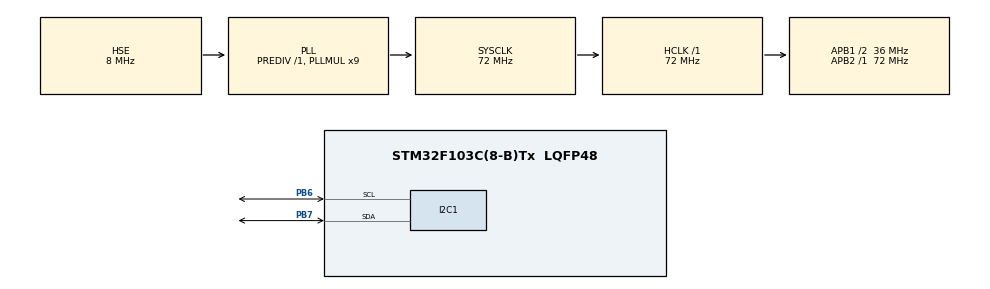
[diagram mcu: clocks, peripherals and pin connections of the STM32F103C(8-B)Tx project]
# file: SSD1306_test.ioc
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I2C1.I2C_Mode=I2C_Fast
Mcu.Family=STM32F1
Mcu.Name=STM32F103C(8-B)Tx
Mcu.Package=LQFP48
NVIC.PriorityGroup=NVIC_PRIORITYGROUP_4
NVIC.TIM4_IRQn=true\:0\:0\:false\:false\:true\:false
NVIC.TimeBase=TIM4_IRQn
NVIC.TimeBaseIP=TIM4
PA13.Mode=Serial_Wire
PA13.Signal=SYS_JTMS-SWDIO
PA14.Mode=Serial_Wire
PA14.Signal=SYS_JTCK-SWCLK
PB3.Signal=SYS_JTDO-TRACESWO
PB6.Mode=I2C
PB6.Signal=I2C1_SCL
PB7.Mode=I2C
PB7.Signal=I2C1_SDA
PD0-OSC_IN.Mode=HSE-External-Oscillator
PD0-OSC_IN.Signal=RCC_OSC_IN
PD1-OSC_OUT.Mode=HSE-External-Oscillator
PD1-OSC_OUT.Signal=RCC_OSC_OUT
ProjectManager.HeapSize=0x200
ProjectManager.StackSize=0x400
ProjectManager.TargetToolchain=SW4STM32
RCC.AHBFreq_Value=72000000
RCC.APB1CLKDivider=RCC_HCLK_DIV2
RCC.APB1Freq_Value=36000000
RCC.APB1TimFreq_Value=72000000
RCC.APB2Freq_Value=72000000
RCC.APB2TimFreq_Value=72000000
RCC.HCLKFreq_Value=72000000
RCC.PLLMUL=RCC_PLL_MUL9
RCC.PLLSourceVirtual=RCC_PLLSOURCE_HSE
RCC.SYSCLKFreq_VALUE=72000000
RCC.SYSCLKSource=RCC_SYSCLKSOURCE_PLLCLK
RCC.USBFreq_Value=72000000
VP_SYS_VS_tim4.Mode=TIM4
board=custom

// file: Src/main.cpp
/* USER CODE BEGIN Header */
/**
  ******************************************************************************
  * @file           : main.c
  * @brief          : Main program body
  ******************************************************************************
  ** This notice applies to any and all portions of this file
  * that are not between comment pairs USER CODE BEGIN and
  * USER CODE END. Other portions of this file, whether
  * inserted by the user or by software development tools
  * are owned by their respective copyright owners.
  *
  * COPYRIGHT(c) 2019 STMicroelectronics
  *
  * Redistribution and use in source and binary forms, with or without modification,
  * are permitted provided that the following conditions are met:
  *   1. Redistributions of source code must retain the above copyright notice,
  *      this list of conditions and the following disclaimer.
  *   2. Redistributions in binary form must reproduce the above copyright notice,
  *      this list of conditions and the following disclaimer in the documentation
  *      and/or other materials provided with the distribution.
  *   3. Neither the name of STMicroelectronics nor the names of its contributors
  *      may be used to endorse or promote products derived from this software
  *      without specific prior written permission.
  *
  * THIS SOFTWARE IS PROVIDED BY THE COPYRIGHT HOLDERS AND CONTRIBUTORS "AS IS"
  * AND ANY EXPRESS OR IMPLIED WARRANTIES, INCLUDING, BUT NOT LIMITED TO, THE
  * IMPLIED WARRANTIES OF MERCHANTABILITY AND FITNESS FOR A PARTICULAR PURPOSE ARE
  * DISCLAIMED. IN NO EVENT SHALL THE COPYRIGHT HOLDER OR CONTRIBUTORS BE LIABLE
  * FOR ANY DIRECT, INDIRECT, INCIDENTAL, SPECIAL, EXEMPLARY, OR CONSEQUENTIAL
  * DAMAGES (INCLUDING, BUT NOT LIMITED TO, PROCUREMENT OF SUBSTITUTE GOODS OR
  * SERVICES; LOSS OF USE, DATA, OR PROFITS; OR BUSINESS INTERRUPTION) HOWEVER
  * CAUSED AND ON ANY THEORY OF LIABILITY, WHETHER IN CONTRACT, STRICT LIABILITY,
  * OR TORT (INCLUDING NEGLIGENCE OR OTHERWISE) ARISING IN ANY WAY OUT OF THE USE
  * OF THIS SOFTWARE, EVEN IF ADVISED OF THE POSSIBILITY OF SUCH DAMAGE.
  *
  ******************************************************************************
  */
/* USER CODE END Header */

#include "main.h"
#include <string.h>

/* USER CODE BEGIN PD */
#define SCALESPEED 0.025
/* USER CODE END PD */

I2C_HandleTypeDef hi2c1;

void SystemClock_Config(void);
static void MX_GPIO_Init(void);
static void MX_I2C1_Init(void);

/* USER CODE BEGIN 0 */
Scene3D scene(64, 32, 6, 6); // 128x64

// model defines

/* USER CODE END 0 */

int main(void)
{
  /* USER CODE BEGIN 1 */
	// INIT MODEL

	Matrix<> vertex(4, 8, ver);
	Matrix<int> faces(9, 3, fa);
	Matrix<int> im(3, 2, ima); // 1, 24

	scene.addModel(vertex, faces, im);
//	scene.addModel(vertex, faces, im);
//	scene.addModel(vertex, faces, im);
//	scene.addModel(vertex, faces, im);

//	scene.addModel(vertex, faces, im);
  /* USER CODE END 1 */

  /* MCU Configuration--------------------------------------------------------*/

  /* Reset of all peripherals, Initializes the Flash interface and the Systick. */
  HAL_Init();

  /* Configure the system clock */
  SystemClock_Config();

  /* Initialize all configured peripherals */
  MX_GPIO_Init();
  MX_I2C1_Init();

  /* USER CODE BEGIN 2 */
  uint32_t end = 0;
  uint32_t start;
  uint32_t scalingCount = 1;
  bool scalingD = true;
  int fps3d = 0, fpsre = 0;
  ssd1306_Init();
  scene.apply(translation3D(0,-2,0));
  /* USER CODE END 2 */

  /* Infinite loop */
  while (1)
  {
	  start = HAL_GetTick();

	  scene.Clear();
	  scene.render();

	  // transforms
	  scene.apply(rotationY(3.14/24));
	  scene.apply(rotationX(3.14/36));

//	  if (scalingD && scalingCount < 10)
//	  {
//		  scene.apply(scaling3D(1 - SCALESPEED, 1 - SCALESPEED, 1 - SCALESPEED));
//		  scalingCount++;
//	  }
//	  else
//		  if (scalingCount > 0)
//		  {
//			  scalingD = false;
//			  scene.apply(scaling3D(1 + SCALESPEED, 1 + SCALESPEED, 1 + SCALESPEED));
//			  scalingCount--;
//		  }
//		  else
//		  {
//			  scene.apply(scaling3D(1 - SCALESPEED, 1 - SCALESPEED, 1 - SCALESPEED));
//			  scalingD = true;
//			  scalingCount = 1;
//		  }

	  end = HAL_GetTick();

	  // 3D engine FPS count
	  // char buff[8];
	  // fps3d = 1000 / (end - start);

	  // display all FPS
	  // snprintf(buff, sizeof(buff), "%d", fps3d);
	  // ssd1306_SetCursor(0,0);
	  // ssd1306_WriteString(buff, Font_7x10, White);
	  snprintf(buff, sizeof(buff), "%d", fpsre);
	  ssd1306_SetCursor(0,0);
	  ssd1306_WriteString(buff, Font_7x10, White);

	  ssd1306_UpdateScreen();

	  // Real FPS count
	  end = HAL_GetTick();
	  fpsre = 1000 / (end - start);

	  ssd1306_UpdateScreen();

//	  ssd1306_SetCursor(0,0);
//	  ssd1306_WriteString("HELLO!", Font_7x10, White); //пишем надпись в выставленной позиции шрифтом "Font_7x10" белым цветом.
//
//	  for (int i = 0; i < 63; i+=4)
//		  ssd1306_DrawLine(47, 31,  127, i,  White);
//	  ssd1306_DrawFilledRectangle(15, 15, 31, 31, White);
//	  ssd1306_DrawFilledCircle(63, 31, 10, White);
//
//
//	  ssd1306_UpdateScreen();
//
//	  ssd1306_Fill(Black);

  }
}

void SystemClock_Config(void)
{
  RCC_OscInitTypeDef RCC_OscInitStruct = {0};
  RCC_ClkInitTypeDef RCC_ClkInitStruct = {0};

  /**Initializes the CPU, AHB and APB busses clocks
  */
  RCC_OscInitStruct.OscillatorType = RCC_OSCILLATORTYPE_HSE;
  RCC_OscInitStruct.HSEState = RCC_HSE_ON;
  RCC_OscInitStruct.HSEPredivValue = RCC_HSE_PREDIV_DIV1;
  RCC_OscInitStruct.HSIState = RCC_HSI_ON;
  RCC_OscInitStruct.PLL.PLLState = RCC_PLL_ON;
  RCC_OscInitStruct.PLL.PLLSource = RCC_PLLSOURCE_HSE;
  RCC_OscInitStruct.PLL.PLLMUL = RCC_PLL_MUL9;
  if (HAL_RCC_OscConfig(&RCC_OscInitStruct) != HAL_OK)
  {
    Error_Handler();
  }
  /**Initializes the CPU, AHB and APB busses clocks
  */
  RCC_ClkInitStruct.ClockType = RCC_CLOCKTYPE_HCLK|RCC_CLOCKTYPE_SYSCLK
                              |RCC_CLOCKTYPE_PCLK1|RCC_CLOCKTYPE_PCLK2;
  RCC_ClkInitStruct.SYSCLKSource = RCC_SYSCLKSOURCE_PLLCLK;
  RCC_ClkInitStruct.AHBCLKDivider = RCC_SYSCLK_DIV1;
  RCC_ClkInitStruct.APB1CLKDivider = RCC_HCLK_DIV2;
  RCC_ClkInitStruct.APB2CLKDivider = RCC_HCLK_DIV1;

  if (HAL_RCC_ClockConfig(&RCC_ClkInitStruct, FLASH_LATENCY_2) != HAL_OK)
  {
    Error_Handler();
  }
}

static void MX_I2C1_Init(void)
{

  hi2c1.Instance = I2C1;
  hi2c1.Init.ClockSpeed = 400000;
  hi2c1.Init.DutyCycle = I2C_DUTYCYCLE_2;
  hi2c1.Init.OwnAddress1 = 0x15; // def 0
  hi2c1.Init.AddressingMode = I2C_ADDRESSINGMODE_7BIT;
  hi2c1.Init.DualAddressMode = I2C_DUALADDRESS_DISABLE;
  hi2c1.Init.OwnAddress2 = 0;
  hi2c1.Init.GeneralCallMode = I2C_GENERALCALL_DISABLE;
  hi2c1.Init.NoStretchMode = I2C_NOSTRETCH_DISABLE;
  if (HAL_I2C_Init(&hi2c1) != HAL_OK)
  {
    Error_Handler();
  }

}

static void MX_GPIO_Init(void)
{
  /* GPIO Ports Clock Enable */
  __HAL_RCC_GPIOD_CLK_ENABLE();
  __HAL_RCC_GPIOA_CLK_ENABLE();
  __HAL_RCC_GPIOB_CLK_ENABLE();
}

void HAL_TIM_PeriodElapsedCallback(TIM_HandleTypeDef *htim)
{
  if (htim->Instance == TIM4) {
    HAL_IncTick();
  }
}

void Error_Handler(void)
{
}

/************************ (C) COPYRIGHT STMicroelectronics *****END OF FILE****/
